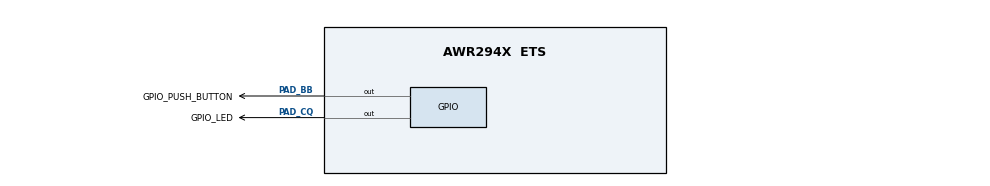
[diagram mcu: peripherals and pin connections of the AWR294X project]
/**
 * @cliArgs --device "AWR294X" --part "Default" --package "ETS" --context "r5fss0-0" --product "MCU_PLUS_SDK_AWR2944@10.00.00"
 * @versions {"tool":"1.22.0+3893"}
 */

/**
 * Import the modules used in this configuration.
 */
const adcbuf     = scripting.addModule("/drivers/adcbuf/adcbuf", {}, false);
const adcbuf1    = adcbuf.addInstance();
const crc        = scripting.addModule("/drivers/crc/crc", {}, false);
const crc1       = crc.addInstance();
const edma       = scripting.addModule("/drivers/edma/edma", {}, false);
const edma1      = edma.addInstance();
const gpio       = scripting.addModule("/drivers/gpio/gpio", {}, false);
const gpio1      = gpio.addInstance();
const gpio2      = gpio.addInstance();
const hwa        = scripting.addModule("/drivers/hwa/hwa", {}, false);
const hwa1       = hwa.addInstance();
const ipc        = scripting.addModule("/drivers/ipc/ipc");
const qspi       = scripting.addModule("/drivers/qspi/qspi", {}, false);
const qspi1      = qspi.addInstance();
const clock      = scripting.addModule("/kernel/dpl/clock");
const debug_log  = scripting.addModule("/kernel/dpl/debug_log");
const mpu_armv7  = scripting.addModule("/kernel/dpl/mpu_armv7", {}, false);
const mpu_armv71 = mpu_armv7.addInstance();
const mpu_armv72 = mpu_armv7.addInstance();
const mpu_armv73 = mpu_armv7.addInstance();
const mpu_armv74 = mpu_armv7.addInstance();
const mpu_armv75 = mpu_armv7.addInstance();
const mpu_armv76 = mpu_armv7.addInstance();
const enet_cpsw  = scripting.addModule("/networking/enet_cpsw/enet_cpsw", {}, false);
const enet_cpsw1 = enet_cpsw.addInstance();

/**
 * Write custom configuration values to the imported modules.
 */
adcbuf1.$name = "CONFIG_ADCBUF0";

crc1.$name = "CONFIG_CRC0";

gpio1.$name                = "GPIO_PUSH_BUTTON";
gpio1.trigType             = "RISE_EDGE";
gpio1.GPIO.$assign         = "GPIO";
gpio1.GPIO.gpioPin.$assign = "PAD_BB";

gpio2.$name                = "GPIO_LED";
gpio2.pinDir               = "OUTPUT";
gpio2.trigType             = "RISE_EDGE";
gpio2.GPIO.$assign         = "GPIO";
gpio2.GPIO.gpioPin.$assign = "PAD_CQ";

hwa1.$name = "CONFIG_HWA0";

ipc.c66ss0   = "NONE";
ipc.r5fss0_1 = "NONE";

qspi1.$name = "CONFIG_QSPI0";

debug_log.enableUartLog           = true;
debug_log.uartLog.$name           = "CONFIG_UART0";
debug_log.uartLog.UART.$assign    = "UARTA";
debug_log.uartLog.UART.RX.$assign = "PAD_DA";
debug_log.uartLog.UART.TX.$assign = "PAD_DB";

edma1.$name                             = "CONFIG_EDMA0";
qspi1.edmaConfig                        = edma1;
debug_log.uartLog.edmaConfig            = edma1;
edma1.regionId                          = 0;
edma1.initParamSet                      = "TRUE";
edma1.instance                          = "EDMA_DSS_A";
edma1.edmaRmDmaCh[0].$name              = "CONFIG_EDMA_RM0";
edma1.edmaRmDmaCh[0].resourceType       = scripting.forceWrite("ownDmaCh");
edma1.edmaRmDmaCh[0].startIndex         = 0;
edma1.edmaRmDmaCh[0].endIndex           = 63;
edma1.edmaRmQdmaCh[0].$name             = "CONFIG_EDMA_RM1";
edma1.edmaRmTcc[0].$name                = "CONFIG_EDMA_RM2";
edma1.edmaRmTcc[0].startIndex           = 0;
edma1.edmaRmTcc[0].endIndex             = 63;
edma1.edmaRmParam[0].$name              = "CONFIG_EDMA_RM3";
edma1.edmaRmParam[0].startIndex         = 0;
edma1.edmaRmParam[0].endIndex           = 127;
edma1.edmaRmReservedDmaCh[0].$name      = "CONFIG_EDMA_RM4";
edma1.edmaRmReservedDmaCh[0].startIndex = 0;
edma1.edmaRmReservedDmaCh[0].endIndex   = 0;

mpu_armv71.$name        = "CONFIG_MPU_REGION0";
mpu_armv71.attributes   = "Device";
mpu_armv71.allowExecute = false;

mpu_armv72.$name = "CONFIG_MPU_REGION1";
mpu_armv72.size  = 14;

mpu_armv73.$name    = "CONFIG_MPU_REGION2";
mpu_armv73.baseAddr = 0x80000;
mpu_armv73.size     = 14;

mpu_armv74.$name    = "CONFIG_MPU_REGION3";
mpu_armv74.baseAddr = 0x10200000;
mpu_armv74.size     = 20;

mpu_armv75.$name        = "CONFIG_MPU_REGION4";
mpu_armv75.attributes   = "NonCached";
mpu_armv75.allowExecute = false;
mpu_armv75.baseAddr     = 0x1021C000;
mpu_armv75.size         = 14;

mpu_armv76.$name        = "CONFIG_MPU_REGION5";
mpu_armv76.attributes   = "NonCached";
mpu_armv76.allowExecute = false;
mpu_armv76.baseAddr     = 0x88000000;
mpu_armv76.size         = 20;

enet_cpsw1.$name                           = "CONFIG_ENET_CPSW0";
enet_cpsw1.PktInfoOnlyEnable               = true;
enet_cpsw1.LargePoolPktCount               = 32;
enet_cpsw1.cptsHostRxTsEn                  = false;
enet_cpsw1.AppLinkUpPortMask               = "ALL_PORTS";
enet_cpsw1.txDmaChannel[0].$name           = "ENET_DMA_TX_CH0";
enet_cpsw1.rxDmaChannel[0].$name           = "ENET_DMA_RX_CH0";
enet_cpsw1.pinmux[0].$name                 = "ENET_CPSW_PINMUX0";
enet_cpsw1.pinmux[0].phyToMacInterfaceMode = "RGMII";
enet_cpsw1.netifInstance.create(1);
enet_cpsw1.netifInstance[0].$name          = "NETIF_INST_ID0";

/**
 * Pinmux solution for unlocked pins/peripherals. This ensures that minor changes to the automatic solver in a future
 * version of the tool will not impact the pinmux you originally saw.  These lines can be completely deleted in order to
 * re-solve from scratch.
 */
qspi1.QSPI["0"].$suggestSolution                 = "PAD_AL";
qspi1.QSPI["1"].$suggestSolution                 = "PAD_AM";
qspi1.QSPI["2"].$suggestSolution                 = "PAD_AN";
qspi1.QSPI["3"].$suggestSolution                 = "PAD_AO";
qspi1.QSPI.$suggestSolution                      = "QSPI0";
qspi1.QSPI.CLK.$suggestSolution                  = "PAD_AP";
qspi1.QSPI.CS.$suggestSolution                   = "PAD_AQ";
enet_cpsw1.pinmux[0].CPTS.$suggestSolution       = "CPTS0";
enet_cpsw1.pinmux[0].MDIO.$suggestSolution       = "MDIO0";
enet_cpsw1.pinmux[0].MDIO.DATA.$suggestSolution  = "PAD_CM";
enet_cpsw1.pinmux[0].MDIO.CLK.$suggestSolution   = "PAD_CN";
enet_cpsw1.pinmux[0].RGMII.$suggestSolution      = "RGMII0";
enet_cpsw1.pinmux[0].RGMII.RD0.$suggestSolution  = "PAD_CL";
enet_cpsw1.pinmux[0].RGMII.RD1.$suggestSolution  = "PAD_CK";
enet_cpsw1.pinmux[0].RGMII.RD2.$suggestSolution  = "PAD_CJ";
enet_cpsw1.pinmux[0].RGMII.RD3.$suggestSolution  = "PAD_CI";
enet_cpsw1.pinmux[0].RGMII.RCTL.$suggestSolution = "PAD_CB";
enet_cpsw1.pinmux[0].RGMII.RCLK.$suggestSolution = "PAD_CH";
enet_cpsw1.pinmux[0].RGMII.TD0.$suggestSolution  = "PAD_CF";
enet_cpsw1.pinmux[0].RGMII.TD1.$suggestSolution  = "PAD_CE";
enet_cpsw1.pinmux[0].RGMII.TD2.$suggestSolution  = "PAD_CD";
enet_cpsw1.pinmux[0].RGMII.TD3.$suggestSolution  = "PAD_CC";
enet_cpsw1.pinmux[0].RGMII.TCTL.$suggestSolution = "PAD_CA";
enet_cpsw1.pinmux[0].RGMII.TCLK.$suggestSolution = "PAD_CG";
